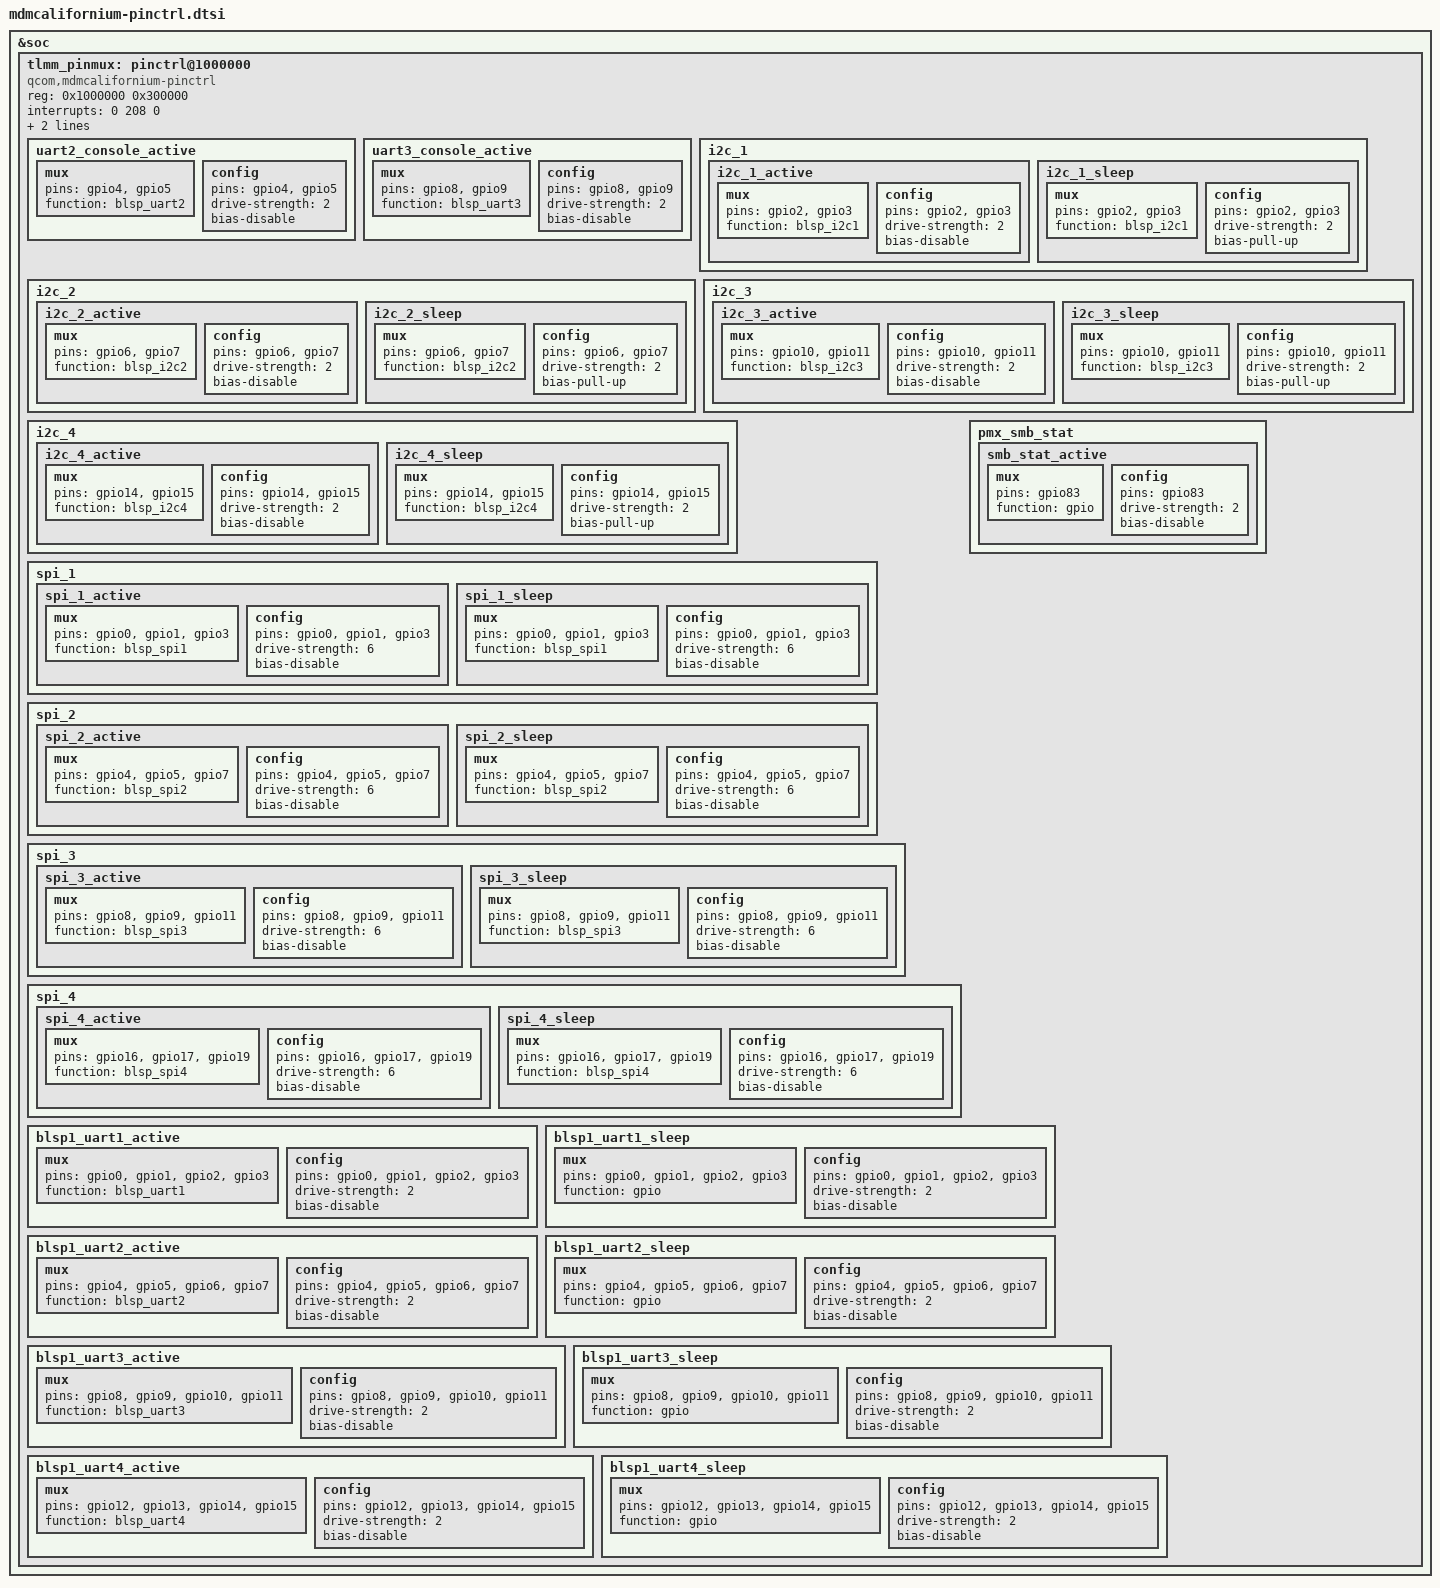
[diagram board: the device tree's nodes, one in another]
/* Copyright (c) 2015, The Linux Foundation. All rights reserved.
 *
 * This program is free software; you can redistribute it and/or modify
 * it under the terms of the GNU General Public License version 2 and
 * only version 2 as published by the Free Software Foundation.
 *
 * This program is distributed in the hope that it will be useful,
 * but WITHOUT ANY WARRANTY; without even the implied warranty of
 * MERCHANTABILITY or FITNESS FOR A PARTICULAR PURPOSE.  See the
 * GNU General Public License for more details.
 */

&soc {
	tlmm_pinmux: pinctrl@1000000 {
		compatible = "qcom,mdmcalifornium-pinctrl";
		reg = <0x1000000 0x300000>;
		interrupts = <0 208 0>;
		gpio-controller;
		#gpio-cells = <2>;
		interrupt-controller;
		#interrupt-cells = <2>;

		uart2_console_active: uart2_console_active {
			mux {
				pins = "gpio4", "gpio5";
				function = "blsp_uart2";
			};
			config {
				pins = "gpio4", "gpio5";
				drive-strength = <2>;
				bias-disable;
			};
		};

		uart3_console_active: uart3_console_active {
			mux {
				pins = "gpio8", "gpio9";
				function = "blsp_uart3";
			};
			config {
				pins = "gpio8", "gpio9";
				drive-strength = <2>;
				bias-disable;
			};
		};

		/* I2C CONFIGURATION */
		i2c_1 {
			i2c_1_active: i2c_1_active {
				mux {
					pins = "gpio2", "gpio3";
					function = "blsp_i2c1";
				};

				config {
					pins = "gpio2", "gpio3";
					drive-strength = <2>;
					bias-disable;
				};
			};

			i2c_1_sleep: i2c_1_sleep {
				mux {
					pins = "gpio2", "gpio3";
					function = "blsp_i2c1";
				};

				config {
					pins = "gpio2", "gpio3";
					drive-strength = <2>;
					bias-pull-up;
				};
			};
		};

		i2c_2 {
			i2c_2_active: i2c_2_active {
				mux {
					pins = "gpio6", "gpio7";
					function = "blsp_i2c2";
				};

				config {
					pins = "gpio6", "gpio7";
					drive-strength = <2>;
					bias-disable;
				};
			};

			i2c_2_sleep: i2c_2_sleep {
				mux {
					pins = "gpio6", "gpio7";
					function = "blsp_i2c2";
				};

				config {
					pins = "gpio6", "gpio7";
					drive-strength = <2>;
					bias-pull-up;
				};
			};
		};

		i2c_3 {
			i2c_3_active: i2c_3_active {
				mux {
					pins = "gpio10", "gpio11";
					function = "blsp_i2c3";
				};

				config {
					pins = "gpio10", "gpio11";
					drive-strength = <2>;
					bias-disable;
				};
			};

			i2c_3_sleep: i2c_3_sleep {
				mux {
					pins = "gpio10", "gpio11";
					function = "blsp_i2c3";
				};

				config {
					pins = "gpio10", "gpio11";
					drive-strength = <2>;
					bias-pull-up;
				};
			};
		};

		i2c_4 {
			i2c_4_active: i2c_4_active {
				mux {
					pins = "gpio14", "gpio15";
					function = "blsp_i2c4";
				};

				config {
					pins = "gpio14", "gpio15";
					drive-strength = <2>;
					bias-disable;
				};
			};

			i2c_4_sleep: i2c_4_sleep {
				mux {
					pins = "gpio14", "gpio15";
					function = "blsp_i2c4";
				};

				config {
					pins = "gpio14", "gpio15";
					drive-strength = <2>;
					bias-pull-up;
				};
			};
		};

		/* SPI CONFIGURATION */
		spi_1 {
			spi_1_active: spi_1_active {
				mux {
					pins = "gpio0", "gpio1", "gpio3";
					function = "blsp_spi1";
				};

				config {
					pins = "gpio0", "gpio1", "gpio3";
					drive-strength = <6>;
					bias-disable;
				};
			};

			spi_1_sleep: spi_1_sleep {
				mux {
					pins = "gpio0", "gpio1", "gpio3";
					function = "blsp_spi1";
				};

				config {
					pins = "gpio0", "gpio1", "gpio3";
					drive-strength = <6>;
					bias-disable;
				};
			};
		};

		spi_2 {
			spi_2_active: spi_2_active {
				mux {
					pins = "gpio4", "gpio5", "gpio7";
					function = "blsp_spi2";
				};

				config {
					pins = "gpio4", "gpio5", "gpio7";
					drive-strength = <6>;
					bias-disable;
				};
			};

			spi_2_sleep: spi_2_sleep {
				mux {
					pins = "gpio4", "gpio5", "gpio7";
					function = "blsp_spi2";
				};

				config {
					pins = "gpio4", "gpio5", "gpio7";
					drive-strength = <6>;
					bias-disable;
				};
			};
		};

		spi_3 {
			spi_3_active: spi_3_active {
				mux {
					pins = "gpio8", "gpio9", "gpio11";
					function = "blsp_spi3";
				};

				config {
					pins = "gpio8", "gpio9", "gpio11";
					drive-strength = <6>;
					bias-disable;
				};
			};

			spi_3_sleep: spi_3_sleep {
				mux {
					pins = "gpio8", "gpio9", "gpio11";
					function = "blsp_spi3";
				};

				config {
					pins = "gpio8", "gpio9", "gpio11";
					drive-strength = <6>;
					bias-disable;
				};
			};
		};

		spi_4 {
			spi_4_active: spi_4_active {
				mux {
					pins = "gpio16", "gpio17", "gpio19";
					function = "blsp_spi4";
				};

				config {
					pins = "gpio16", "gpio17", "gpio19";
					drive-strength = <6>;
					bias-disable;
				};
			};

			spi_4_sleep: spi_4_sleep {
				mux {
					pins = "gpio16", "gpio17", "gpio19";
					function = "blsp_spi4";
				};

				config {
					pins = "gpio16", "gpio17", "gpio19";
					drive-strength = <6>;
					bias-disable;
				};
			};
		};

		/* SMB CONFIGURATION */
		pmx_smb_stat {
			smb_stat_active: smb_stat_active {
				mux {
					pins = "gpio83";
					function = "gpio";
				};

				config {
					pins = "gpio83";
					drive-strength = <2>;
					bias-disable;
				};
			};
		};

		/* UART HS CONFIGURATION */

		blsp1_uart1_active: blsp1_uart1_active {
			mux {
				pins = "gpio0", "gpio1", "gpio2", "gpio3";
				function = "blsp_uart1";
			};

			config {
				pins = "gpio0", "gpio1", "gpio2", "gpio3";
				drive-strength = <2>;
				bias-disable;
			};
		};

		blsp1_uart1_sleep: blsp1_uart1_sleep {
			mux {
				pins = "gpio0", "gpio1", "gpio2", "gpio3";
				function = "gpio";
			};

			config {
				pins = "gpio0", "gpio1", "gpio2", "gpio3";
				drive-strength = <2>;
				bias-disable;
			};
		};
		blsp1_uart2_active: blsp1_uart2_active {
			mux {
				pins = "gpio4", "gpio5", "gpio6", "gpio7";
				function = "blsp_uart2";
			};

			config {
				pins = "gpio4", "gpio5", "gpio6", "gpio7";
				drive-strength = <2>;
				bias-disable;
			};
		};

		blsp1_uart2_sleep: blsp1_uart2_sleep {
			mux {
				pins = "gpio4", "gpio5", "gpio6", "gpio7";
				function = "gpio";
			};

			config {
				pins = "gpio4", "gpio5", "gpio6", "gpio7";
				drive-strength = <2>;
				bias-disable;
			};
		};
		blsp1_uart3_active: blsp1_uart3_active {
			mux {
				pins = "gpio8", "gpio9", "gpio10", "gpio11";
				function = "blsp_uart3";
			};

			config {
				pins = "gpio8", "gpio9", "gpio10", "gpio11";
				drive-strength = <2>;
				bias-disable;
			};
		};

		blsp1_uart3_sleep: blsp1_uart3_sleep {
			mux {
				pins = "gpio8", "gpio9", "gpio10", "gpio11";
				function = "gpio";
			};

			config {
				pins = "gpio8", "gpio9", "gpio10", "gpio11";
				drive-strength = <2>;
				bias-disable;
			};
		};

		blsp1_uart4_active: blsp1_uart4_active {
			mux {
				pins = "gpio12", "gpio13", "gpio14", "gpio15";
				function = "blsp_uart4";
			};

			config {
				pins = "gpio12", "gpio13", "gpio14", "gpio15";
				drive-strength = <2>;
				bias-disable;
			};
		};

		blsp1_uart4_sleep: blsp1_uart4_sleep {
			mux {
				pins = "gpio12", "gpio13", "gpio14", "gpio15";
				function = "gpio";
			};

			config {
				pins = "gpio12", "gpio13", "gpio14", "gpio15";
				drive-strength = <2>;
				bias-disable;
			};
		};
	};
};
